AUTOSAR XML (schema 4-0-3)
package /AUTOSAR_BswM  # Basic Software Mode Manager
package /AUTOSAR_BswM/PortInterfaces_OsApp_CORE1_PARTITION0
  sender receiver interface BswMGenInterface_SwcMode_ReqPort: is-service=true
    data AppMode: type=uint8
package /AUTOSAR_BswM/SwComponentTypes_OsApp_CORE0_PARTITION0
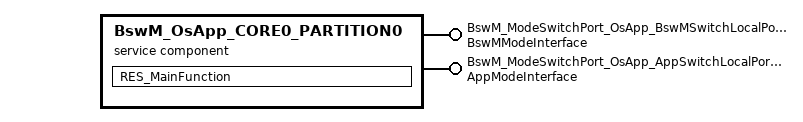
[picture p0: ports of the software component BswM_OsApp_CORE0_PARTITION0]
  service sw component type BswM_OsApp_CORE0_PARTITION0
    provide port BswM_ModeSwitchPort_OsApp_BswMSwitchLocalPort_Switch_Rte_CORE0_PARTITION0: provided-interface=BswMModeInterface
    provide port BswM_ModeSwitchPort_OsApp_AppSwitchLocalPort_Switch_Rte_CORE0_PARTITION0: provided-interface=AppModeInterface
    behavior BswMInternalBehavior: data-type-mapping=[BswMModeMapping, ApplicationModeMapping], handle-termination-and-restart=CAN-BE-TERMINATED-AND-RESTARTED
      included-mode-declaration-group-sets:
        mode-declaration-group=BswMModeGroup, prefix=BSWM_
        mode-declaration-group=ApplicationModeGroup, prefix=BSWM_
      runnable RES_MainFunction: symbol=BswM_1_OsApp_CORE0_PARTITION0_MainFunction
        mode switch point RES_MainFunction_to_BswMSwitchLocalPort_Rte: mode-group=BswM_ModeSwitchPort_OsApp_CORE0_PARTITION0_BswMSwitchLocalPort_Rte.BswMMode
        mode switch point RES_MainFunction_to_AppSwitchLocalPort_Rte: mode-group=BswM_ModeSwitchPort_OsApp_CORE0_PARTITION0_AppSwitchLocalPort_Rte.AppMode
package /AUTOSAR_BswM/SwComponentTypes_OsApp_CORE1_PARTITION0
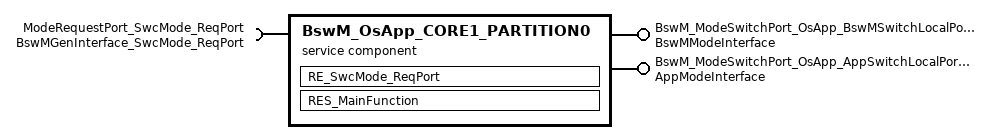
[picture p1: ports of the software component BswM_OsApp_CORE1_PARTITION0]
  service sw component type BswM_OsApp_CORE1_PARTITION0
    provide port BswM_ModeSwitchPort_OsApp_BswMSwitchLocalPort_SlaveCore_Switch_Rte_CORE1_PARTITION0: provided-interface=BswMModeInterface
    provide port BswM_ModeSwitchPort_OsApp_AppSwitchLocalPort_Switch_Rte_CORE1_PARTITION0: provided-interface=AppModeInterface
    require port ModeRequestPort_SwcMode_ReqPort: nonqueued-receiver-com-spec{data-element=AppMode, init-value=4}, required-interface=BswMGenInterface_SwcMode_ReqPort
    behavior BswMInternalBehavior: data-type-mapping=[BswMModeMapping, ApplicationModeMapping], handle-termination-and-restart=CAN-BE-TERMINATED-AND-RESTARTED
      data received event DRE_SwcMode_ReqPort: start-on-event=RE_SwcMode_ReqPort, data=ModeRequestPort_SwcMode_ReqPort.AppMode
      included-mode-declaration-group-sets:
        mode-declaration-group=BswMModeGroup, prefix=BSWM_
        mode-declaration-group=ApplicationModeGroup, prefix=BSWM_
      runnable RE_SwcMode_ReqPort: symbol=BswM_1_OsApp_CORE1_PARTITION0_MRPFunc_SwcMode_ReqPort
        data-receive-point-by-arguments:
          access RE_SwcMode_ReqPort_to_SwcMode_ReqPort: accessed-variable=ModeRequestPort_SwcMode_ReqPort.AppMode
      runnable RES_MainFunction: symbol=BswM_1_OsApp_CORE1_PARTITION0_MainFunction
        mode switch point RES_MainFunction_to_BswMSwitchLocalPort_SlaveCore_Rte: mode-group=BswM_ModeSwitchPort_OsApp_CORE1_PARTITION0_BswMSwitchLocalPort_SlaveCore_Rte.BswMMode
        mode switch point RES_MainFunction_to_AppSwitchLocalPort_Rte: mode-group=BswM_ModeSwitchPort_OsApp_CORE1_PARTITION0_AppSwitchLocalPort_Rte.AppMode
package /AUTOSAR_BswM/SwcImplementations
  swc implementation BswMImplementation_OsApp_CORE0_PARTITION0: programming-language=C, sw-version=1.1.1, vendor-id=1, behavior=BswM_OsApp_CORE0_PARTITION0/BswMInternalBehavior
    code-descriptors:
      code BswMImplementationEB: artifact-descriptors=autosar-engineering-object={short-label=BswMEngObject, category=SWSRC}
    resource consumption Resources
  swc implementation BswMImplementation_OsApp_CORE1_PARTITION0: programming-language=C, sw-version=1.1.1, vendor-id=1, behavior=BswM_OsApp_CORE1_PARTITION0/BswMInternalBehavior
    code-descriptors:
      code BswMImplementationEB: artifact-descriptors=autosar-engineering-object={short-label=BswMEngObject, category=SWSRC}
    resource consumption Resources
